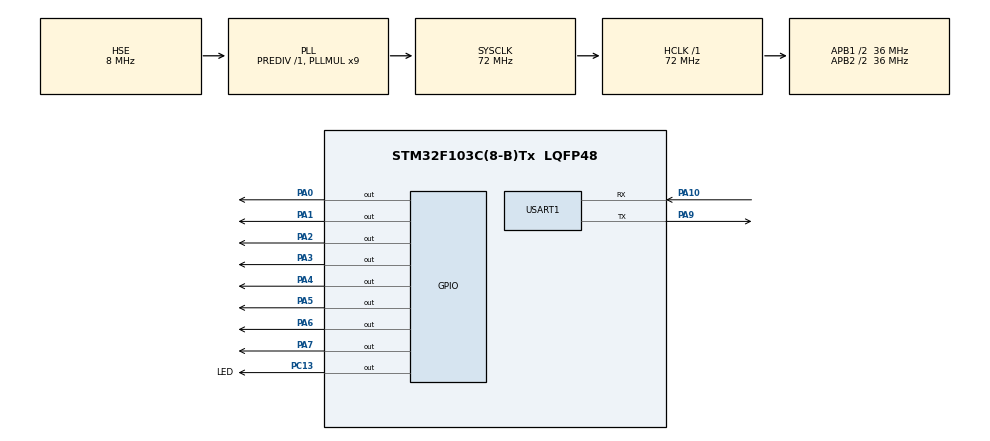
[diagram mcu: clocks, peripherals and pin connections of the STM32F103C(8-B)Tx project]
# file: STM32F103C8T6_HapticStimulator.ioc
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Mcu.Family=STM32F1
Mcu.Name=STM32F103C(8-B)Tx
Mcu.Package=LQFP48
NVIC.PriorityGroup=NVIC_PRIORITYGROUP_4
NVIC.TIM2_IRQn=true\:0\:0\:false\:false\:true\:true\:true
NVIC.USART1_IRQn=true\:0\:0\:false\:false\:true\:true\:true
PA0-WKUP.GPIO_Speed=GPIO_SPEED_FREQ_HIGH
PA0-WKUP.Signal=GPIO_Output
PA1.GPIO_Speed=GPIO_SPEED_FREQ_HIGH
PA1.Signal=GPIO_Output
PA10.Mode=Asynchronous
PA10.Signal=USART1_RX
PA13.Mode=Serial_Wire
PA13.Signal=SYS_JTMS-SWDIO
PA14.Mode=Serial_Wire
PA14.Signal=SYS_JTCK-SWCLK
PA2.GPIO_Speed=GPIO_SPEED_FREQ_HIGH
PA2.Signal=GPIO_Output
PA3.GPIO_Speed=GPIO_SPEED_FREQ_HIGH
PA3.Signal=GPIO_Output
PA4.GPIO_Speed=GPIO_SPEED_FREQ_HIGH
PA4.Signal=GPIO_Output
PA5.GPIO_Speed=GPIO_SPEED_FREQ_HIGH
PA5.Signal=GPIO_Output
PA6.GPIO_Speed=GPIO_SPEED_FREQ_HIGH
PA6.Signal=GPIO_Output
PA7.GPIO_Speed=GPIO_SPEED_FREQ_HIGH
PA7.Signal=GPIO_Output
PA9.Mode=Asynchronous
PA9.Signal=USART1_TX
PC13-TAMPER-RTC.GPIO_Label=LED
PC13-TAMPER-RTC.GPIO_Speed=GPIO_SPEED_FREQ_HIGH
PC13-TAMPER-RTC.PinState=GPIO_PIN_SET
PC13-TAMPER-RTC.Signal=GPIO_Output
PD0-OSC_IN.Mode=HSE-External-Oscillator
PD0-OSC_IN.Signal=RCC_OSC_IN
PD1-OSC_OUT.Mode=HSE-External-Oscillator
PD1-OSC_OUT.Signal=RCC_OSC_OUT
ProjectManager.HeapSize=0x200
ProjectManager.StackSize=0x400
ProjectManager.TargetToolchain=STM32CubeIDE
RCC.AHBFreq_Value=72000000
RCC.APB1CLKDivider=RCC_HCLK_DIV2
RCC.APB1Freq_Value=36000000
RCC.APB1TimFreq_Value=72000000
RCC.APB2CLKDivider=RCC_HCLK_DIV2
RCC.APB2Freq_Value=36000000
RCC.APB2TimFreq_Value=72000000
RCC.HCLKFreq_Value=72000000
RCC.PLLMUL=RCC_PLL_MUL9
RCC.PLLSourceVirtual=RCC_PLLSOURCE_HSE
RCC.SYSCLKFreq_VALUE=72000000
RCC.SYSCLKSource=RCC_SYSCLKSOURCE_PLLCLK
RCC.USBFreq_Value=72000000
TIM2.Period=99
TIM2.Prescaler=7200
USART1.VirtualMode=VM_ASYNC
VP_TIM2_VS_ClockSourceINT.Mode=Internal
board=custom

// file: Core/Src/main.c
/* USER CODE BEGIN Header */
/**
  ******************************************************************************
  * @file           : main.c
  * @brief          : Main program body
  ******************************************************************************
  * @attention
  *
  * <h2><center>&copy; Copyright (c) 2020 STMicroelectronics.
  * All rights reserved.</center></h2>
  *
  * This software component is licensed by ST under BSD 3-Clause license,
  * the "License"; You may not use this file except in compliance with the
  * License. You may obtain a copy of the License at:
  *                        opensource.org/licenses/BSD-3-Clause
  *
  ******************************************************************************
  */
/* USER CODE END Header */
#include "main.h"

/* USER CODE BEGIN Includes */
#include "myLibrary.h"
/* USER CODE END Includes */

TIM_HandleTypeDef htim2;

UART_HandleTypeDef huart1;

void SystemClock_Config(void);
static void MX_GPIO_Init(void);
static void MX_USART1_UART_Init(void);
static void MX_TIM2_Init(void);

int main(void)
{

  /* MCU Configuration--------------------------------------------------------*/

  /* Reset of all peripherals, Initializes the Flash interface and the Systick. */
  HAL_Init();

  /* Configure the system clock */
  SystemClock_Config();

  /* Initialize all configured peripherals */
  MX_GPIO_Init();
  MX_USART1_UART_Init();
  MX_TIM2_Init();
  /* USER CODE BEGIN 2 */
  HAL_TIM_Base_Start_IT(&htim2);
  __HAL_UART_DISABLE_IT(&huart1, UART_IT_RXNE);
  HAL_Delay(500);
  HAL_UART_Transmit(&huart1, (uint8_t*)"AT+NAMEHaptic Stimulator", strlen("AT+NAMEHaptic Stimulator"), 500);
  HAL_Delay(1500);
  __HAL_UART_ENABLE_IT(&huart1, UART_IT_RXNE);
  /* USER CODE END 2 */

  /* Infinite loop */
  while (1)
  {

    /* USER CODE BEGIN 3 */
	GPIOA->ODR = value;
	HAL_Delay(2);
	GPIOA->ODR = 0;
	HAL_Delay(8);
	if(messageHandlerFlag)
	{
		messageHandlerFlag = 0;
		messageHandler();
	}
  }
  /* USER CODE END 3 */
}

void SystemClock_Config(void)
{
  RCC_OscInitTypeDef RCC_OscInitStruct = {0};
  RCC_ClkInitTypeDef RCC_ClkInitStruct = {0};

  /** Initializes the RCC Oscillators according to the specified parameters
  * in the RCC_OscInitTypeDef structure.
  */
  RCC_OscInitStruct.OscillatorType = RCC_OSCILLATORTYPE_HSE;
  RCC_OscInitStruct.HSEState = RCC_HSE_ON;
  RCC_OscInitStruct.HSEPredivValue = RCC_HSE_PREDIV_DIV1;
  RCC_OscInitStruct.HSIState = RCC_HSI_ON;
  RCC_OscInitStruct.PLL.PLLState = RCC_PLL_ON;
  RCC_OscInitStruct.PLL.PLLSource = RCC_PLLSOURCE_HSE;
  RCC_OscInitStruct.PLL.PLLMUL = RCC_PLL_MUL9;
  if (HAL_RCC_OscConfig(&RCC_OscInitStruct) != HAL_OK)
  {
    Error_Handler();
  }
  /** Initializes the CPU, AHB and APB buses clocks
  */
  RCC_ClkInitStruct.ClockType = RCC_CLOCKTYPE_HCLK|RCC_CLOCKTYPE_SYSCLK
                              |RCC_CLOCKTYPE_PCLK1|RCC_CLOCKTYPE_PCLK2;
  RCC_ClkInitStruct.SYSCLKSource = RCC_SYSCLKSOURCE_PLLCLK;
  RCC_ClkInitStruct.AHBCLKDivider = RCC_SYSCLK_DIV1;
  RCC_ClkInitStruct.APB1CLKDivider = RCC_HCLK_DIV2;
  RCC_ClkInitStruct.APB2CLKDivider = RCC_HCLK_DIV2;

  if (HAL_RCC_ClockConfig(&RCC_ClkInitStruct, FLASH_LATENCY_2) != HAL_OK)
  {
    Error_Handler();
  }
}

static void MX_TIM2_Init(void)
{

  TIM_ClockConfigTypeDef sClockSourceConfig = {0};
  TIM_MasterConfigTypeDef sMasterConfig = {0};

  htim2.Instance = TIM2;
  htim2.Init.Prescaler = 7200;
  htim2.Init.CounterMode = TIM_COUNTERMODE_UP;
  htim2.Init.Period = 99;
  htim2.Init.ClockDivision = TIM_CLOCKDIVISION_DIV1;
  htim2.Init.AutoReloadPreload = TIM_AUTORELOAD_PRELOAD_DISABLE;
  if (HAL_TIM_Base_Init(&htim2) != HAL_OK)
  {
    Error_Handler();
  }
  sClockSourceConfig.ClockSource = TIM_CLOCKSOURCE_INTERNAL;
  if (HAL_TIM_ConfigClockSource(&htim2, &sClockSourceConfig) != HAL_OK)
  {
    Error_Handler();
  }
  sMasterConfig.MasterOutputTrigger = TIM_TRGO_RESET;
  sMasterConfig.MasterSlaveMode = TIM_MASTERSLAVEMODE_DISABLE;
  if (HAL_TIMEx_MasterConfigSynchronization(&htim2, &sMasterConfig) != HAL_OK)
  {
    Error_Handler();
  }

}

static void MX_USART1_UART_Init(void)
{

  huart1.Instance = USART1;
  huart1.Init.BaudRate = 115200;
  huart1.Init.WordLength = UART_WORDLENGTH_8B;
  huart1.Init.StopBits = UART_STOPBITS_1;
  huart1.Init.Parity = UART_PARITY_NONE;
  huart1.Init.Mode = UART_MODE_TX_RX;
  huart1.Init.HwFlowCtl = UART_HWCONTROL_NONE;
  huart1.Init.OverSampling = UART_OVERSAMPLING_16;
  if (HAL_UART_Init(&huart1) != HAL_OK)
  {
    Error_Handler();
  }

}

static void MX_GPIO_Init(void)
{
  GPIO_InitTypeDef GPIO_InitStruct = {0};

  /* GPIO Ports Clock Enable */
  __HAL_RCC_GPIOC_CLK_ENABLE();
  __HAL_RCC_GPIOD_CLK_ENABLE();
  __HAL_RCC_GPIOA_CLK_ENABLE();

  /*Configure GPIO pin Output Level */
  HAL_GPIO_WritePin(LED_GPIO_Port, LED_Pin, GPIO_PIN_SET);

  /*Configure GPIO pin Output Level */
  HAL_GPIO_WritePin(GPIOA, GPIO_PIN_0|GPIO_PIN_1|GPIO_PIN_2|GPIO_PIN_3
                          |GPIO_PIN_4|GPIO_PIN_5|GPIO_PIN_6|GPIO_PIN_7, GPIO_PIN_RESET);

  /*Configure GPIO pin : LED_Pin */
  GPIO_InitStruct.Pin = LED_Pin;
  GPIO_InitStruct.Mode = GPIO_MODE_OUTPUT_PP;
  GPIO_InitStruct.Pull = GPIO_NOPULL;
  GPIO_InitStruct.Speed = GPIO_SPEED_FREQ_HIGH;
  HAL_GPIO_Init(LED_GPIO_Port, &GPIO_InitStruct);

  /*Configure GPIO pins : PA0 PA1 PA2 PA3
                           PA4 PA5 PA6 PA7 */
  GPIO_InitStruct.Pin = GPIO_PIN_0|GPIO_PIN_1|GPIO_PIN_2|GPIO_PIN_3
                          |GPIO_PIN_4|GPIO_PIN_5|GPIO_PIN_6|GPIO_PIN_7;
  GPIO_InitStruct.Mode = GPIO_MODE_OUTPUT_PP;
  GPIO_InitStruct.Pull = GPIO_NOPULL;
  GPIO_InitStruct.Speed = GPIO_SPEED_FREQ_HIGH;
  HAL_GPIO_Init(GPIOA, &GPIO_InitStruct);

}

void Error_Handler(void)
{
}

/************************ (C) COPYRIGHT STMicroelectronics *****END OF FILE****/
